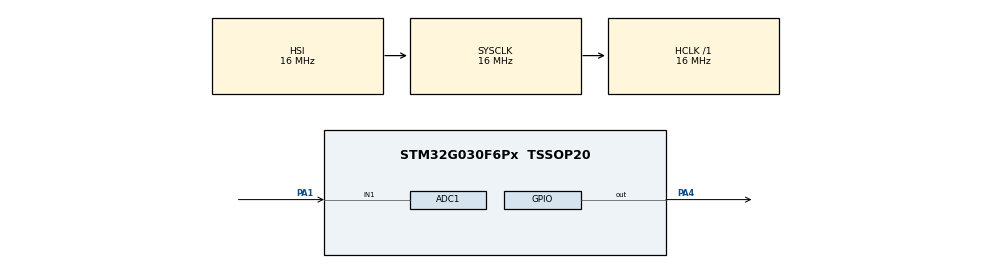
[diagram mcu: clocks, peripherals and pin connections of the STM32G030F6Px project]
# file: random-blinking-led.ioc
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ADC1.Channel-3\#ChannelRegularConversion=ADC_CHANNEL_1
ADC1.NbrOfConversionFlag=1
ADC1.Rank-3\#ChannelRegularConversion=1
ADC1.SamplingTime-3\#ChannelRegularConversion=ADC_SAMPLINGTIME_COMMON_1
ADC1.SelectedChannel=ADC_CHANNEL_1
ADC1.master=1
Mcu.Family=STM32G0
Mcu.Name=STM32G030F6Px
Mcu.Package=TSSOP20
NVIC.ADC1_IRQn=true\:0\:0\:false\:false\:true\:true\:true\:true
NVIC.TIM3_IRQn=true\:0\:0\:false\:false\:true\:true\:true\:true
PA1.Mode=IN1
PA1.Signal=ADC1_IN1
PA14-BOOT0__PA15.StandardMode=true
PA4.Signal=GPIO_Output
PB0__PB1__PB2__PA8.StandardMode=true
PB3__PB4__PB5__PB6.StandardMode=true
PB7__PB8.StandardMode=true
PC14-OSC32_IN\ (PC14)__PB9.StandardMode=true
ProjectManager.HeapSize=0x200
ProjectManager.StackSize=0x400
ProjectManager.TargetToolchain=STM32CubeIDE
RCC.AHBFreq_Value=16000000
RCC.CortexFreq_Value=16000000
RCC.EXTERNAL_CLOCK_VALUE=12288000
RCC.HCLKFreq_Value=16000000
RCC.HSE_VALUE=8000000
RCC.HSI_VALUE=16000000
RCC.LSE_VALUE=32768
RCC.SYSCLKFreq_VALUE=16000000
RCC.VCOOutputFreq_Value=128000000
TIM3.Period=9999
TIM3.Prescaler=15
VP_TIM3_VS_ClockSourceINT.Mode=Internal
board=custom

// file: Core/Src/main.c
/* USER CODE BEGIN Header */
/**
  ******************************************************************************
  * @file           : main.c
  * @brief          : Main program body
  ******************************************************************************
  * @attention
  *
  * Copyright (c) 2026 STMicroelectronics.
  * All rights reserved.
  *
  * This software is licensed under terms that can be found in the LICENSE file
  * in the root directory of this software component.
  * If no LICENSE file comes with this software, it is provided AS-IS.
  *
  ******************************************************************************
  */
/* USER CODE END Header */
#include "main.h"

/* USER CODE BEGIN Includes */
#include <stdlib.h>
#include "random_utils.h"
/* USER CODE END Includes */

ADC_HandleTypeDef hadc1;

TIM_HandleTypeDef htim3;

void SystemClock_Config(void);
static void MX_GPIO_Init(void);
static void MX_ADC1_Init(void);

static void MX_TIM3_Init(void);
/* USER CODE BEGIN PFP */
volatile uint8_t tim3_flag= 0;
volatile uint8_t r= 50; // start blink counter with any number
volatile uint16_t LEDcounter= 0;

/* USER CODE END PFP */

int main(void)
{

  /* MCU Configuration--------------------------------------------------------*/

  /* Reset of all peripherals, Initializes the Flash interface and the Systick. */
  HAL_Init();

  /* Configure the system clock */
  SystemClock_Config();

  /* Initialize all configured peripherals */
  MX_GPIO_Init();
  MX_ADC1_Init();
  MX_TIM3_Init();
  /* USER CODE BEGIN 2 */
  HAL_TIM_Base_Start_IT(&htim3);
  init_random(&hadc1, &htim3);
  /* USER CODE END 2 */

  /* Infinite loop */
  while (1)
  {

    /* USER CODE BEGIN 3 */
	  if(tim3_flag == 1){ // This happens every 10ms
		  tim3_flag= 0;

		  LEDcounter++;
		  // The if statement below is executed every time the LEDcounter
		  // counter becomes bigger than a random time between 100 and 1000ms
		  // So essentially the LED changes state every 'x' random milisseconds
		  if(LEDcounter >= r){
			  r = random_10_100(); // upon entering the LED toggle function,
			  	  	  	  	  	  // a new random number is picked for the
			  	  	  	  	  	  // next cycle.
			  LEDcounter= 0;

			  HAL_GPIO_TogglePin(GPIOA, GPIO_PIN_4);
		  }

	  }
	  maybe_reseed(); // this will reseed the random number from time to time
  }
  /* USER CODE END 3 */
}

void SystemClock_Config(void)
{
  RCC_OscInitTypeDef RCC_OscInitStruct = {0};
  RCC_ClkInitTypeDef RCC_ClkInitStruct = {0};

  /** Configure the main internal regulator output voltage
  */
  HAL_PWREx_ControlVoltageScaling(PWR_REGULATOR_VOLTAGE_SCALE1);

  /** Initializes the RCC Oscillators according to the specified parameters
  * in the RCC_OscInitTypeDef structure.
  */
  RCC_OscInitStruct.OscillatorType = RCC_OSCILLATORTYPE_HSI;
  RCC_OscInitStruct.HSIState = RCC_HSI_ON;
  RCC_OscInitStruct.HSIDiv = RCC_HSI_DIV1;
  RCC_OscInitStruct.HSICalibrationValue = RCC_HSICALIBRATION_DEFAULT;
  RCC_OscInitStruct.PLL.PLLState = RCC_PLL_NONE;
  if (HAL_RCC_OscConfig(&RCC_OscInitStruct) != HAL_OK)
  {
    Error_Handler();
  }

  /** Initializes the CPU, AHB and APB buses clocks
  */
  RCC_ClkInitStruct.ClockType = RCC_CLOCKTYPE_HCLK|RCC_CLOCKTYPE_SYSCLK
                              |RCC_CLOCKTYPE_PCLK1;
  RCC_ClkInitStruct.SYSCLKSource = RCC_SYSCLKSOURCE_HSI;
  RCC_ClkInitStruct.AHBCLKDivider = RCC_SYSCLK_DIV1;
  RCC_ClkInitStruct.APB1CLKDivider = RCC_HCLK_DIV1;

  if (HAL_RCC_ClockConfig(&RCC_ClkInitStruct, FLASH_LATENCY_0) != HAL_OK)
  {
    Error_Handler();
  }
}

static void MX_ADC1_Init(void)
{

  ADC_ChannelConfTypeDef sConfig = {0};

  /** Configure the global features of the ADC (Clock, Resolution, Data Alignment and number of conversion)
  */
  hadc1.Instance = ADC1;
  hadc1.Init.ClockPrescaler = ADC_CLOCK_SYNC_PCLK_DIV2;
  hadc1.Init.Resolution = ADC_RESOLUTION_12B;
  hadc1.Init.DataAlign = ADC_DATAALIGN_RIGHT;
  hadc1.Init.ScanConvMode = ADC_SCAN_DISABLE;
  hadc1.Init.EOCSelection = ADC_EOC_SINGLE_CONV;
  hadc1.Init.LowPowerAutoWait = DISABLE;
  hadc1.Init.LowPowerAutoPowerOff = DISABLE;
  hadc1.Init.ContinuousConvMode = DISABLE;
  hadc1.Init.NbrOfConversion = 1;
  hadc1.Init.DiscontinuousConvMode = DISABLE;
  hadc1.Init.ExternalTrigConv = ADC_SOFTWARE_START;
  hadc1.Init.ExternalTrigConvEdge = ADC_EXTERNALTRIGCONVEDGE_NONE;
  hadc1.Init.DMAContinuousRequests = DISABLE;
  hadc1.Init.Overrun = ADC_OVR_DATA_PRESERVED;
  hadc1.Init.SamplingTimeCommon1 = ADC_SAMPLETIME_1CYCLE_5;
  hadc1.Init.SamplingTimeCommon2 = ADC_SAMPLETIME_1CYCLE_5;
  hadc1.Init.OversamplingMode = DISABLE;
  hadc1.Init.TriggerFrequencyMode = ADC_TRIGGER_FREQ_HIGH;
  if (HAL_ADC_Init(&hadc1) != HAL_OK)
  {
    Error_Handler();
  }

  /** Configure Regular Channel
  */
  sConfig.Channel = ADC_CHANNEL_1;
  sConfig.Rank = ADC_REGULAR_RANK_1;
  sConfig.SamplingTime = ADC_SAMPLINGTIME_COMMON_1;
  if (HAL_ADC_ConfigChannel(&hadc1, &sConfig) != HAL_OK)
  {
    Error_Handler();
  }

}

static void MX_TIM3_Init(void)
{

  TIM_ClockConfigTypeDef sClockSourceConfig = {0};
  TIM_MasterConfigTypeDef sMasterConfig = {0};

  htim3.Instance = TIM3;
  htim3.Init.Prescaler = 15;
  htim3.Init.CounterMode = TIM_COUNTERMODE_UP;
  htim3.Init.Period = 9999;
  htim3.Init.ClockDivision = TIM_CLOCKDIVISION_DIV1;
  htim3.Init.AutoReloadPreload = TIM_AUTORELOAD_PRELOAD_DISABLE;
  if (HAL_TIM_Base_Init(&htim3) != HAL_OK)
  {
    Error_Handler();
  }
  sClockSourceConfig.ClockSource = TIM_CLOCKSOURCE_INTERNAL;
  if (HAL_TIM_ConfigClockSource(&htim3, &sClockSourceConfig) != HAL_OK)
  {
    Error_Handler();
  }
  sMasterConfig.MasterOutputTrigger = TIM_TRGO_RESET;
  sMasterConfig.MasterSlaveMode = TIM_MASTERSLAVEMODE_DISABLE;
  if (HAL_TIMEx_MasterConfigSynchronization(&htim3, &sMasterConfig) != HAL_OK)
  {
    Error_Handler();
  }

}

static void MX_GPIO_Init(void)
{
  GPIO_InitTypeDef GPIO_InitStruct = {0};

  /* GPIO Ports Clock Enable */
  __HAL_RCC_GPIOA_CLK_ENABLE();

  /*Configure GPIO pin Output Level */
  HAL_GPIO_WritePin(GPIOA, GPIO_PIN_4, GPIO_PIN_RESET);

  /*Configure GPIO pin : PA4 */
  GPIO_InitStruct.Pin = GPIO_PIN_4;
  GPIO_InitStruct.Mode = GPIO_MODE_OUTPUT_PP;
  GPIO_InitStruct.Pull = GPIO_NOPULL;
  GPIO_InitStruct.Speed = GPIO_SPEED_FREQ_LOW;
  HAL_GPIO_Init(GPIOA, &GPIO_InitStruct);

}

/* USER CODE BEGIN 4 */

void HAL_TIM_PeriodElapsedCallback(TIM_HandleTypeDef *htim)
{
    if (htim->Instance == TIM3)
    {
    	tim3_flag= 1; // allows the interrupt-following code in the main
    					// loop to execute
    }
}
/* USER CODE END 4 */

void Error_Handler(void)
{
  __disable_irq();
  while (1)
  {
  }
}
